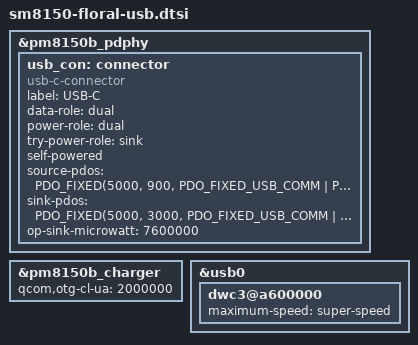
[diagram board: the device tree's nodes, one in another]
#include <dt-bindings/usb/pd.h>

&pm8150b_pdphy {
	usb_con: connector {
		compatible = "usb-c-connector";
		label = "USB-C";
		data-role = "dual";
		power-role = "dual";
		try-power-role = "sink";
		self-powered;
		source-pdos = <PDO_FIXED(5000, 900,
					 PDO_FIXED_USB_COMM
					 | PDO_FIXED_DATA_SWAP
					 | PDO_FIXED_DUAL_ROLE)>;
		sink-pdos = <PDO_FIXED(5000, 3000, PDO_FIXED_USB_COMM
						   | PDO_FIXED_DATA_SWAP
						   | PDO_FIXED_DUAL_ROLE)
			    PDO_FIXED(9000, 3000, 0)>;
		op-sink-microwatt = <7600000>;
	};
};

&pm8150b_charger {
	qcom,otg-cl-ua = <2000000>;
};

&usb0 {
	dwc3@a600000 {
		maximum-speed = "super-speed";
	};
};
